# CS32F036x register map
File version: 1.0
Registers are 32-bit, read-write, reset 0x0 unless marked. A register's access mark holds for its fields unless they carry their own. Offsets are from the block's base; [hi:lo] are bit positions.

## I2C1 — Inter-integrated circuit
Base 0x40005400
Same registers: I2C2 0x40005800
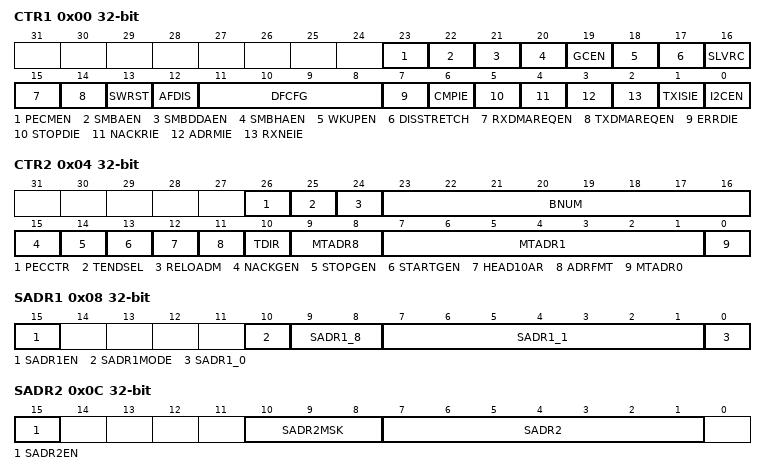
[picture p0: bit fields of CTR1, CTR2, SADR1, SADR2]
0x00 CTR1 access per field — Control register 1
  [23] PECMEN rw — PEC mode enable
  [22] SMBAEN rw — SMBUS alert enable
  [21] SMBDDAEN rw — Enable bit for SMBus Device Default address
  [20] SMBHAEN rw — Enable bit for SMBus Host address
  [19] GCEN rw — Enable bit for General call
  [18] WKUPEN rw — Enable bit for Stop mode Wakeup
  [17] DISSTRETCH rw — Disable clock stretching
  [16] SLVRC rw — Slave response control
  [15] RXDMAREQEN rw — Enable bit for Reception DMA requests
  [14] TXDMAREQEN rw — Enable bit for Transmission DMA requests
  [13] SWRST wo — Software reset
  [12] AFDIS rw — Analog filter Disable
  [11:8] DFCFG rw — Digital filter configuration
  [7] ERRDIE rw — Enable bit for Error detection interrupt
  [6] CMPIE rw — Enable bit for Transfer complete interrupt
  [5] STOPDIE rw — Enable bit for STOP detection interrupt
  [4] NACKRIE rw — Enable bit for Not acknowledge received interrupt
  [3] ADRMIE rw — Enable bit for Address match interrupt
  [2] RXNEIE rw — Enable bit for RX interrupt
  [1] TXISIE rw — Enable bit for TX interrupt
  [0] I2CEN rw — I2C enable
0x04 CTR2 — Control register 2
  [26] PECCTR — PEC byte control
  [25] TENDSEL — Tranfer end mode selection (master mode)
  [24] RELOADM — Bytes number reload mode
  [23:16] BNUM — Bytes number
  [15] NACKGEN — Generate a NACK on I2C bus (slave mode)
  [14] STOPGEN — Generate a Stop on I2C bus (master mode)
  [13] STARTGEN — Generate a Start on I2C bus
  [12] HEAD10AR — 10-bit address header only read direction (master receiver mode)
  [11] ADRFMT — Addressing format (master mode)
  [10] TDIR — Direction of Transfer (master mode)
  [9:8] MTADR8 — Master transfer address bit 9:8 on I2C bus
  [7:1] MTADR1 — Master transfer address bit 7:1 on I2C bus
  [0] MTADR0 — Master transfer address bit 0 on I2C bus
0x08 SADR1 — I2C slave address 1 register
  [15] SADR1EN — Slave Address 1 enable
  [10] SADR1MODE — Slave Address 1 10-bit mode
  [9:8] SADR1_8 — Slave Address 1
  [7:1] SADR1_1 — Slave Address 1
  [0] SADR1_0 — Slave Address 1
0x0C SADR2 — I2C slave address 2 register
  [15] SADR2EN — Slave Address 2 enable
  [10:8] SADR2MSK — Slave Address 2 masks
  [7:1] SADR2 — Slave Address 2
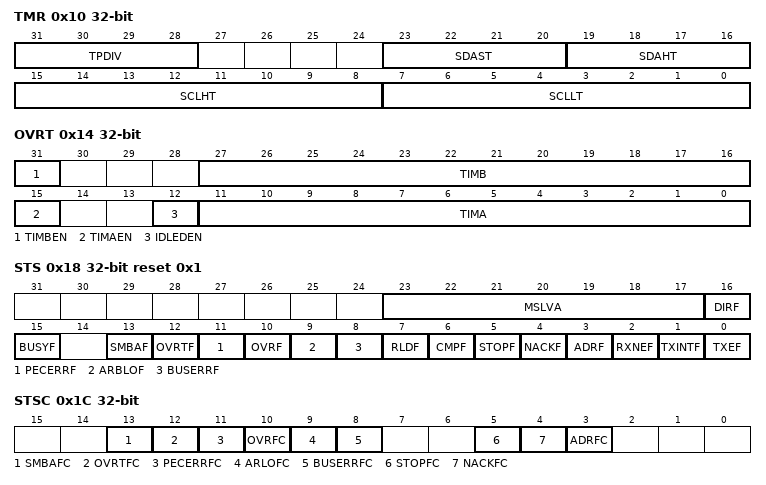
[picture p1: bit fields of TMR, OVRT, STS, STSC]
0x10 TMR — I2C timing register
  [31:28] TPDIV — Timing pre-divider
  [23:20] SDAST — SDA setup time
  [19:16] SDAHT — SDA hold time
  [15:8] SCLHT — Master mode SCL high time
  [7:0] SCLLT — Master mode SCL low time
0x14 OVRT — I2C overtime register
  [31] TIMBEN — timer B enable
  [27:16] TIMB — Bus overtime B
  [15] TIMAEN — timer A enable
  [12] IDLEDEN — Idle clock overtime detection
  [11:0] TIMA — Bus overtime A
0x18 STS access per field reset 0x1 — Status register
  [23:17] MSLVA ro — Matched Slave Address
  [16] DIRF ro — Slave Transfer direction flag
  [15] BUSYF ro — Bus busy flag
  [13] SMBAF ro — SMBus alert flag
  [12] OVRTF ro — Overtime or tLOW detection flag
  [11] PECERRF ro — PEC Error flag
  [10] OVRF ro — Slave Overflow/Underflow flag
  [9] ARBLOF ro — Arbitration lost flag
  [8] BUSERRF ro — Bus error flag
  [7] RLDF ro — Reload flag
  [6] CMPF ro — Master mode Transfer Complete flag
  [5] STOPF ro — Stop detection flag
  [4] NACKF ro — NACK received flag
  [3] ADRF ro — Slave mode Address matched flag
  [2] RXNEF ro — Data register not empty in receiving mode
  [1] TXINTF rw — Transmit interrupt flag
  [0] TXEF rw — Data register empty flag in transmitting mode
0x1C STSC wo — Status clear register
  [13] SMBAFC — SMBus alert flag clear
  [12] OVRTFC — Overtime detection flag clear
  [11] PECERRFC — PEC Error flag clear
  [10] OVRFC — Slave Overflow/Underflow flag clear
  [9] ARLOFC — Arbitration Lost flag clear
  [8] BUSERRFC — Bus error flag clear
  [5] STOPFC — Stop detection flag clear
  [4] NACKFC — NACK received flag clear
  [3] ADRFC — Slave mode Address matched flag clear
0x20 PECCODE ro — I2C received PEC code register
  [7:0] PECCODE — Received PEC code
0x24 RXBUF ro — Receive buffer register
  [7:0] RXBUF
0x28 TXBUF — Transmit buffer register
  [7:0] TXBUF
